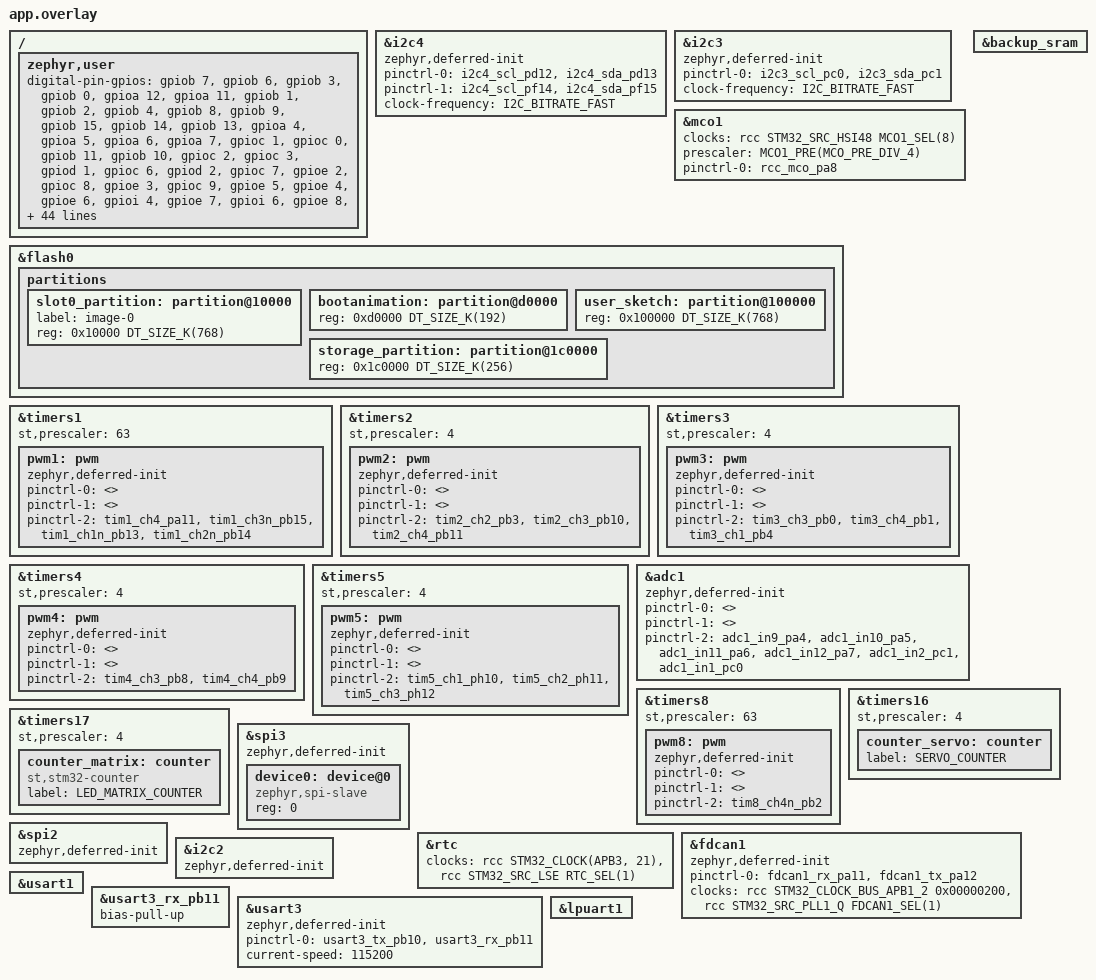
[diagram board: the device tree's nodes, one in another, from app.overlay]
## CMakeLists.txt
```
cmake_minimum_required(VERSION 3.20.0)

set(BOARD_VARIANT "arduino_uno_q")

find_package(Zephyr REQUIRED HINTS $ENV{ZEPHYR_BASE})


#set(ARDUINO_CORE_DIR "~/.arduino15/packages/arduino/hardware/zephyr/0.90.0")
#set(ZEPHYR_EXTRA_MODULES ${ARDUINO_CORE_DIR} )

set(ZEPHYR_EXTRA_MODULES 
    "${ZEPHYR_BASE}/../modules/lib/arduinocore-zephyr"
)

project(myTestSketch)

#set(ARDUINO_CORE_DIR "~/.arduino15/packages/arduino/hardware/zephyr/0.90.0")
set(ARDUINO_CORE_DIR ${ZEPHYR_EXTRA_MODULES})
set(LIB_DIR "~/Arduino/libraries")

target_sources(app PRIVATE 
    src/main.cpp
    ${LIB_DIR}/RF24Ethernet/drivers/net/rf24_netif.c
    ${ARDUINO_CORE_DIR}/cores/arduino/Arduino.h
    ${LIB_DIR}/Arduino_RouterBridge/src/singletons.cpp
    ${LIB_DIR}/Arduino_RouterBridge/src/Arduino_RouterBridge.h
    ${LIB_DIR}/Arduino_RouterBridge/src/routerbridge_provides_serial.h
    ${LIB_DIR}/Arduino_RouterBridge/src/bridge.h
    ${LIB_DIR}/Arduino_RouterBridge/src/monitor.h
    ${LIB_DIR}/ArduinoGraphics/src/ArduinoGraphics.cpp
    ${LIB_DIR}/ArduinoGraphics/src/Image.cpp
    ${LIB_DIR}/RF24/RF24.cpp
    ${LIB_DIR}/RF24Network/RF24Network.cpp
    ${LIB_DIR}/RF24Mesh/RF24Mesh.cpp
    ${LIB_DIR}/RF24Ethernet/RF24Ethernet.cpp
    ${LIB_DIR}/RF24Ethernet/RF24Client.cpp
    ${LIB_DIR}/RF24Ethernet/RF24Server.cpp
    ${LIB_DIR}/RF24Ethernet/RF24Udp.cpp
    ${LIB_DIR}/RF24Ethernet/Dns.cpp
    ${LIB_DIR}/Arduino_RPClite/src/Arduino_RPClite.h
    ${ARDUINO_CORE_DIR}/cores/arduino/new.cpp
)

target_include_directories(app PRIVATE
    #drivers/net
    "${ARDUINO_CORE_DIR}/cores/arduino"
    "${ARDUINO_CORE_DIR}/cores/arduino/api"
    "${ARDUINO_CORE_DIR}/variants/arduino_uno_q_stm32u585xx"
    "${ARDUINO_CORE_DIR}/libraries/SPI"
    "${LIB_DIR}/Arduino_RPClite/src"
    "${LIB_DIR}/MsgPack"
    "${LIB_DIR}/DebugLog"
    "${LIB_DIR}/ArxTypeTraits"
    "${LIB_DIR}/ArxContainer"
    "${LIB_DIR}/RF24"
    "${LIB_DIR}/RF24Network"
    "${LIB_DIR}/RF24Mesh"
    "${LIB_DIR}/RF24Ethernet"
    "${ARDUINO_CORE_DIR}/libraries/Arduino_LED_Matrix/src"
    "${LIB_DIR}/ArduinoGraphics/src"
    "${LIB_DIR}/Arduino_RouterBridge/src"
    ${ZEPHYR_BASE}/../modules/lib/arduinocore-zephyr/loader/
)

target_compile_definitions(app PRIVATE 
    -DCONFIG_BOARD_ARDUINO_UNO_Q
    -DARDUINO_VARIANT="arduino_uno_q_stm32u585xx"
    -DUSE_LWIP=2
    -DRF24ETHERNET_USE_UDP=1
    -DARDUINO
 )
```

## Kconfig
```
# 1. Pull in the baseline Zephyr main Kconfig definitions
source "Kconfig.zephyr"
```

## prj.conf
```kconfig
CONFIG_SERIAL=y
CONFIG_CONSOLE=y
CONFIG_UART_CONSOLE=y


CONFIG_THREAD_LOCAL_STORAGE=n
# Force the build system to initialize the TLS runtime tables
#CONFIG_COMPILER_OPT="-ftls-model=local-exec"
CONFIG_ARM_TRUSTZONE_M=n
CONFIG_TRUSTED_EXECUTION_NONSECURE=y
CONFIG_TRUSTED_EXECUTION_SECURE=y
CONFIG_BUILD_WITH_TFM=y

CONFIG_USB_DEVICE_STACK=n
CONFIG_USB_CDC_ACM=n
CONFIG_USB_DEVICE_INITIALIZE_AT_BOOT=n
CONFIG_USB_DEVICE_PRODUCT="Zephyr Monitor"

CONFIG_LOG=n
CONFIG_LOG_MODE_IMMEDIATE=y


CONFIG_GPIO=y
CONFIG_ARDUINO_ENTRY=y
CONFIG_CPP=y
CONFIG_STD_CPP17=y
CONFIG_GLIBCXX_LIBCPP=y
CONFIG_NEWLIB_LIBC=y
#CONFIG_MINIMAL_LIBC=n

#CONFIG_GLIBCXX_LIBCPP=y
#CONFIG_STD_CPP17=y
#CONFIG_REQUIRES_FULL_LIBCPP=y

CONFIG_SPI=y

# Enable standard device model structures
CONFIG_DEVICE_DEPS=y
CONFIG_POLL=y

CONFIG_SPI_ASYNC=y
CONFIG_SPI_STM32_DMA=n

# Expand stack frames to prevent RTOS buffer overflows
CONFIG_MAIN_STACK_SIZE=16384
CONFIG_SYSTEM_WORKQUEUE_STACK_SIZE=4096
CONFIG_ARDUINO_API=y

CONFIG_LLEXT=n
CONFIG_LLEXT_TYPE_ELF_OBJECT=y

CONFIG_FAULT_DUMP=2
#CONFIG_RESET_ON_FATAL_ERROR=n
CONFIG_FLASH=y
CONFIG_FLASH_MAP=n
CONFIG_MPU_ALLOW_FLASH_WRITE=y
CONFIG_COUNTER=y

CONFIG_USB_DEVICE_VID=0x239A
CONFIG_USB_DEVICE_PID=0x239A

CONFIG_PRINTK=y
CONFIG_SHELL=n
CONFIG_SHELL_BACKEND_SERIAL=y
CONFIG_STDOUT_CONSOLE=y
CONFIG_LOG_BACKEND_UART=y

CONFIG_HEAP_MEM_POOL_SIZE=16384
CONFIG_LLEXT_HEAP_SIZE=256

#CONFIG_FPU=y

CONFIG_ADC=n
CONFIG_DAC=y
CONFIG_PWM=n
CONFIG_I2C_TARGET=y
#CONFIG_DMA=y
CONFIG_MEMC=y
#CONFIG_SPI_ASYNC=y
#CONFIG_SPI_STM32_INTERRUPT=y
#CONFIG_SPI_SLAVE=y
#CONFIG_CAN=y
#CONFIG_CAN_FD_MODE=y
CONFIG_UART_INTERRUPT_DRIVEN=n
CONFIG_UART_LINE_CTRL=y
CONFIG_RTC_STM32=y

CONFIG_DEBUG=y

CONFIG_NET_SOCKETS_SOCKOPT_TLS=n

# Disable TLS credentials management
CONFIG_TLS_CREDENTIALS=n

# Disable Mbed TLS if it is no longer needed by other components
CONFIG_MBEDTLS=n
CONFIG_BOOTLOADER_MCUBOOT=n

CONFIG_DYNAMIC_THREAD=y
CONFIG_DYNAMIC_THREAD_PREFER_ALLOC=y

# Allocate a system heap. Stacks need alignment, so make this 
# significantly larger than your requested stack size.
CONFIG_DYNAMIC_OBJECTS=y
CONFIG_USERSPACE=n
CONFIG_THREAD_STACK_INFO=y
CONFIG_INIT_STACKS=y
CONFIG_DYNAMIC_THREAD_POOL_SIZE=3
CONFIG_DYNAMIC_THREAD_STACK_SIZE=4096

CONFIG_NETWORKING=y
CONFIG_NET_SOCKETS=y

CONFIG_NET_IPV4=y
CONFIG_NET_IPV6=n
CONFIG_NET_TCP=y
CONFIG_NET_UDP=y


CONFIG_NET_PKT_RX_COUNT=24
CONFIG_NET_PKT_TX_COUNT=24
CONFIG_NET_BUF_RX_COUNT=48
CONFIG_NET_BUF_TX_COUNT=48
CONFIG_NET_CONTEXT_NET_PKT_POOL=y

CONFIG_NET_L2_VIRTUAL=n
CONFIG_NET_L2_DUMMY=y

#CONFIG_NET_L2_ETHERNET=n
#CONFIG_NET_ARP=n

CONFIG_NET_TCP_LOG_LEVEL_DBG=n
CONFIG_NET_IPV4_LOG_LEVEL_DBG=n
CONFIG_NET_CORE_LOG_LEVEL_DBG=n
CONFIG_NET_LOG=n
#CONFIG_NET_CONTEXT_LOG_LEVEL_DBG=y
CONFIG_NET_PKT_LOG_LEVEL_DBG=n

CONFIG_NET_PPP=n
CONFIG_NET_TCP_CHECKSUM=n
CONFIG_NET_UDP_CHECKSUM=n

CONFIG_POSIX_API=y
CONFIG_NET_SOCKETS_OFFLOAD=n
CONFIG_NET_RX_STACK_SIZE=8192
CONFIG_NET_TX_STACK_SIZE=8192

CONFIG_NET_IF_UNICAST_IPV4_ADDR_COUNT=2
CONFIG_NET_MAX_CONTEXTS=2

CONFIG_LOG_MODE_DEFERRED=y
CONFIG_LOG_BUFFER_SIZE=16384
CONFIG_LOG_PROCESS_THREAD_STACK_SIZE=4096
CONFIG_COMMON_LIBC_MALLOC_ARENA_SIZE=16384
CONFIG_NET_MAX_CONN=2

CONFIG_NET_TCP_RETRY_COUNT=5


CONFIG_SYS_HEAP_VALIDATE=y

# Catch thread stack overflows immediately via hardware MPU
CONFIG_HW_STACK_PROTECTION=n

# Identify the exact thread causing issues
CONFIG_THREAD_NAME=y
CONFIG_NET_MGMT_EVENT_STACK_SIZE=2048
CONFIG_ZBUS_OBSERVER_NAME=n
```

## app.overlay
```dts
/*
 * Copyright (c) Arduino s.r.l. and/or its affiliated companies
 *
 * SPDX-License-Identifier: Apache-2.0
 */
#include <zephyr/dt-bindings/pwm/stm32_pwm.h>
&i2c4 {
	status = "okay";
	zephyr,deferred-init;
	pinctrl-0 = <&i2c4_scl_pd12 &i2c4_sda_pd13>;
	pinctrl-1 = <&i2c4_scl_pf14 &i2c4_sda_pf15>;
	pinctrl-names = "default", "sleep"; /* TODO: sleep is jmisc mux */
	clock-frequency = <I2C_BITRATE_FAST>;

/*
	gc2145: gc2145@3c {
		status = "okay";
		compatible = "galaxycore,gc2145";
		reg = <0x3c>;
		reset-gpios = <&gpioa 10 GPIO_ACTIVE_LOW>;
		pwdn-gpios = <&gpiod 2 GPIO_ACTIVE_LOW>;

		port {
			gc2145_ep_out: endpoint {
				remote-endpoint = <&dcmi_ep_in>;
			};
		};
	};
*/
};

&i2c3 {
	status = "okay";
	zephyr,deferred-init;
	pinctrl-0 = <&i2c3_scl_pc0 &i2c3_sda_pc1>;
	pinctrl-names = "default"; 
	clock-frequency = <I2C_BITRATE_FAST>;
};

/* clock from HSI48 */
&mco1 {
	status = "okay";
	clocks = <&rcc STM32_SRC_HSI48 MCO1_SEL(8)>;
	prescaler = <MCO1_PRE(MCO_PRE_DIV_4)>;
	pinctrl-0 = <&rcc_mco_pa8>;
	pinctrl-names = "default";
};

&backup_sram {
	status = "okay";
};

/*
&dcmi {
	status = "okay";
	pinctrl-0 = <&dcmi_hsync_pd8 &dcmi_pixclk_pd9 &dcmi_vsync_pi5
				&dcmi_d0_pc6 &dcmi_d1_pc7 &dcmi_d2_pc8 &dcmi_d3_pc9
				&dcmi_d4_pe4 &dcmi_d5_pi4 &dcmi_d6_pi6 &dcmi_d7_pi7>;
	pinctrl-names = "default";
	dmas = <&gpdma1 12 86 (STM32_DMA_PERIPH_TO_MEMORY | STM32_DMA_PERIPH_NO_INC |
			STM32_DMA_MEM_INC | STM32_DMA_PERIPH_32BITS | STM32_DMA_MEM_32BITS |
			STM32_DMA_PRIORITY_HIGH) STM32_DMA_FIFO_1_4>;

	port {
		dcmi_ep_in: endpoint {
			remote-endpoint-label = "gc2145_ep_out";
			bus-width = <8>;
			hsync-active = <0>;
			vsync-active = <0>;
			pclk-sample = <0>;
		};
	};
};
*/

/delete-node/ &slot0_partition;
/delete-node/ &slot1_partition;
/*/delete-node/ &scratch_partition;*/
/delete-node/ &storage_partition;

&flash0 {
	partitions {
		slot0_partition: partition@10000 {
			label = "image-0";
			reg = < 0x10000 DT_SIZE_K(768) >;
		};

		bootanimation: partition@d0000 {
			reg = < 0xd0000 DT_SIZE_K(192) >;
		};

		user_sketch: partition@100000 {
			reg = < 0x100000 DT_SIZE_K(768) >;
		};

		storage_partition: partition@1c0000 {
			reg = < 0x1c0000 DT_SIZE_K(256) >;
		};
	};
};

/* Enable PWM timers */
&timers1 {
	status = "okay";
	st,prescaler = <63>;

	pwm1: pwm {
		status = "okay";
		/* tim1_etr_pa12 is not available for PWM */
		zephyr,deferred-init;
		pinctrl-0 = <>;
		pinctrl-1 = <>;
		pinctrl-2 = <&tim1_ch4_pa11 &tim1_ch3n_pb15 &tim1_ch1n_pb13 &tim1_ch2n_pb14>;
		pinctrl-names = "default", "sleep", "arduino";
	};
};

/* Currently only the pins marked with ~ on the pin headers are enabled */
/* PB10 and PB11 conflict with I2C configuation */
&timers2 {
	status = "okay";
	st,prescaler = <4>;

	pwm2: pwm {
		status = "okay";
		zephyr,deferred-init;
		pinctrl-0 = <>;
		pinctrl-1 = <>;
		pinctrl-2 = <&tim2_ch2_pb3 &tim2_ch3_pb10 &tim2_ch4_pb11>;
		pinctrl-names = "default", "sleep", "arduino";
	};
};

&timers3 {
	status = "okay";
	st,prescaler = <4>;

	pwm3: pwm {
		status = "okay";
		zephyr,deferred-init;
		pinctrl-0 = <>;
		pinctrl-1 = <>;
		pinctrl-2 = <&tim3_ch3_pb0 &tim3_ch4_pb1 &tim3_ch1_pb4>;
		pinctrl-names = "default", "sleep", "arduino";
	};
};

&timers4 {
	status = "okay";
	st,prescaler = <4>;

	pwm4: pwm {
		status = "okay";
		zephyr,deferred-init;
		pinctrl-0 = <>;
		pinctrl-1 = <>;
		pinctrl-2 = <&tim4_ch3_pb8 &tim4_ch4_pb9 /*&tim4_ch1_pb6 &tim4_ch2_pb7*/>;
		pinctrl-names = "default", "sleep", "arduino";
	};
};

&timers5 {
    status = "okay";
	st,prescaler = <4>;

    pwm5: pwm {
        status = "okay";
        zephyr,deferred-init;
        pinctrl-0 = <>;
        pinctrl-1 = <>;
        pinctrl-2 = <&tim5_ch1_ph10 &tim5_ch2_ph11 &tim5_ch3_ph12>;
        pinctrl-names = "default", "sleep", "arduino";
    };
};

&adc1 {
	zephyr,deferred-init;
	pinctrl-0 = <>;
	pinctrl-1 = <>;
	pinctrl-2 = <&adc1_in9_pa4 &adc1_in10_pa5 &adc1_in11_pa6 &adc1_in12_pa7 &adc1_in2_pc1 &adc1_in1_pc0>;
	pinctrl-names = "default", "sleep", "arduino";
	status = "okay";
};

/* Currently only the pins marked with ~ on the pin headers are enabled */
&timers8 {
	status = "okay";
	st,prescaler = <63>;

	pwm8: pwm {
		status = "okay";
		zephyr,deferred-init;
		pinctrl-0 = <>;
		pinctrl-1 = <>;
		pinctrl-2 = <&tim8_ch4n_pb2>;
		pinctrl-names = "default", "sleep", "arduino";
	};
};

&timers16 {
	status = "okay";
	st,prescaler = <4>;

	counter_servo: counter {
		status = "okay";
		label = "SERVO_COUNTER";
	};
};


&timers17 {
	status = "okay";
	st,prescaler = <4>;

	counter_matrix: counter {
		status = "okay";
		label = "LED_MATRIX_COUNTER";
        compatible = "st,stm32-counter";
	};
};

&spi3 {
	zephyr,deferred-init;
	device0: device@0 {
        compatible = "zephyr,spi-slave";
        reg = <0>;
	};
};

&rtc {
    status = "okay";
    clocks = <&rcc STM32_CLOCK(APB3, 21)>,
             <&rcc STM32_SRC_LSE RTC_SEL(1)>;
};

&fdcan1 {
	status = "okay";
	zephyr,deferred-init;
	pinctrl-0 = <&fdcan1_rx_pa11 &fdcan1_tx_pa12>;
	pinctrl-names = "default";
	clocks = <&rcc STM32_CLOCK_BUS_APB1_2 0x00000200>,
		 <&rcc STM32_SRC_PLL1_Q FDCAN1_SEL(1)>;
};

&spi2 {
	zephyr,deferred-init;
};

&i2c2 {
	zephyr,deferred-init;
};

&usart1 {
	/* usart1 is not set as deferred-init to catch early boot logs since it is assigned to zephyr,console */
	status = "okay";
};

&usart3_rx_pb11 {
	bias-pull-up;
};

&usart3 {
	status = "okay";
	zephyr,deferred-init;
	pinctrl-0 = <&usart3_tx_pb10 &usart3_rx_pb11>;
	pinctrl-names = "default";
	current-speed = <115200>;
};


&lpuart1 {
	status = "okay";
};

/ {
	zephyr,user {
		digital-pin-gpios = <&gpiob 7 GPIO_ACTIVE_HIGH>, /* D0 - PB7 */
				    <&gpiob 6 GPIO_ACTIVE_HIGH>, /* D1 - PB6 */
				    <&gpiob 3 GPIO_ACTIVE_HIGH>, /* D2 - PB3 */
				    <&gpiob 0 GPIO_ACTIVE_HIGH>, /* D3 - PB0 */
				    <&gpioa 12 GPIO_ACTIVE_HIGH>, /* D4 - PA12 */
				    <&gpioa 11 GPIO_ACTIVE_HIGH>, /* D5 - PA11 */
				    <&gpiob 1 GPIO_ACTIVE_HIGH>, /* D6 - PB1 */
				    <&gpiob 2 GPIO_ACTIVE_HIGH>, /* D7 - PB2 */
				    <&gpiob 4 GPIO_ACTIVE_HIGH>, /* D8 - PB4 */
				    <&gpiob 8 GPIO_ACTIVE_HIGH>, /* D9 - PB8 */
				    <&gpiob 9 GPIO_ACTIVE_HIGH>, /* D10 - PB9 */
				    <&gpiob 15 GPIO_ACTIVE_HIGH>, /* D11 - PB15 */
				    <&gpiob 14 GPIO_ACTIVE_HIGH>, /* D12 - PB14 */
				    <&gpiob 13 GPIO_ACTIVE_HIGH>, /* D13 - PB13 */

					/* ADCs */
				    <&gpioa 4 GPIO_ACTIVE_HIGH>, /* A0 - PA4 */
				    <&gpioa 5 GPIO_ACTIVE_HIGH>, /* A1 - PA5 */
				    <&gpioa 6 GPIO_ACTIVE_HIGH>, /* A2 - PA6 */
				    <&gpioa 7 GPIO_ACTIVE_HIGH>, /* A3 - PA7 */
				    <&gpioc 1 GPIO_ACTIVE_HIGH>, /* A4 - PC1 */
				    <&gpioc 0 GPIO_ACTIVE_HIGH>, /* A5 - PC0 */

				    <&gpiob 11 GPIO_ACTIVE_HIGH>,  /* D20 - PB11 */
				    <&gpiob 10 GPIO_ACTIVE_HIGH>,  /* D21 - PB10 */

				    <&gpioc 2 GPIO_ACTIVE_HIGH>,        /* JSPI */
				    <&gpioc 3 GPIO_ACTIVE_HIGH>,
				    <&gpiod 1 GPIO_ACTIVE_HIGH>,

				    <&gpioc 6 GPIO_ACTIVE_HIGH>,	/* JMISC */
				    <&gpiod 2 GPIO_ACTIVE_HIGH>,
				    <&gpioc 7 GPIO_ACTIVE_HIGH>,
				    <&gpioe 2 GPIO_ACTIVE_HIGH>,
				    <&gpioc 8 GPIO_ACTIVE_HIGH>,
				    <&gpioe 3 GPIO_ACTIVE_HIGH>,
				    <&gpioc 9 GPIO_ACTIVE_HIGH>,
				    <&gpioe 5 GPIO_ACTIVE_HIGH>,
				    <&gpioe 4 GPIO_ACTIVE_HIGH>,
				    <&gpioe 6 GPIO_ACTIVE_HIGH>,
				    <&gpioi 4 GPIO_ACTIVE_HIGH>,
				    <&gpioe 7 GPIO_ACTIVE_HIGH>,
				    <&gpioi 6 GPIO_ACTIVE_HIGH>,
				    <&gpioe 8 GPIO_ACTIVE_HIGH>,
				    <&gpioi 7 GPIO_ACTIVE_HIGH>,
				    <&gpiof 14 GPIO_ACTIVE_HIGH>,
				    <&gpiod 9 GPIO_ACTIVE_HIGH>,
				    <&gpiof 15 GPIO_ACTIVE_HIGH>,
				    <&gpioi 5 GPIO_ACTIVE_HIGH>,
				    <&gpioa 3 GPIO_ACTIVE_HIGH>,
				    <&gpiod 8 GPIO_ACTIVE_HIGH>,
				    <&gpioa 0 GPIO_ACTIVE_HIGH>,
				    <&gpioa 8 GPIO_ACTIVE_HIGH>,
				    <&gpioa 1 GPIO_ACTIVE_HIGH>,
				    <&gpioa 10 GPIO_ACTIVE_HIGH>,

				    <&gpioh 10 GPIO_ACTIVE_HIGH>,        /* LEDs */
				    <&gpioh 11 GPIO_ACTIVE_HIGH>,
				    <&gpioh 12 GPIO_ACTIVE_HIGH>,
				    <&gpioh 13 GPIO_ACTIVE_HIGH>,
				    <&gpioh 14 GPIO_ACTIVE_HIGH>,
				    <&gpioh 15 GPIO_ACTIVE_HIGH>,

				    <&gpiof 0 GPIO_ACTIVE_HIGH>,        /* LED matrix */
				    <&gpiof 1 GPIO_ACTIVE_HIGH>,
				    <&gpiof 2 GPIO_ACTIVE_HIGH>,
				    <&gpiof 3 GPIO_ACTIVE_HIGH>,
				    <&gpiof 4 GPIO_ACTIVE_HIGH>,
				    <&gpiof 5 GPIO_ACTIVE_HIGH>,
				    <&gpiof 6 GPIO_ACTIVE_HIGH>,
				    <&gpiof 7 GPIO_ACTIVE_HIGH>,
				    <&gpiof 8 GPIO_ACTIVE_HIGH>,
				    <&gpiof 9 GPIO_ACTIVE_HIGH>,
				    <&gpiof 10 GPIO_ACTIVE_HIGH>,
				    <&gpiog 13 GPIO_ACTIVE_HIGH>,       /* Internal SPI RDY */
				    <&gpioa 2 GPIO_ACTIVE_HIGH>,        /* Analog switch for VREF */
				    <&gpioh 3 GPIO_ACTIVE_HIGH>;        /* BOOT0 */

		builtin-led-gpios = <&gpioh 10 GPIO_ACTIVE_HIGH>,
				    <&gpioh 11 GPIO_ACTIVE_HIGH>,
				    <&gpioh 12 GPIO_ACTIVE_HIGH>,
				    <&gpioh 13 GPIO_ACTIVE_HIGH>,
				    <&gpioh 14 GPIO_ACTIVE_HIGH>,
				    <&gpioh 15 GPIO_ACTIVE_HIGH>;

		/* PWM pin mapping - Digital pins with their timer channels */
		/* Currently only the pins marked with ~ on the pin headers are enabled */
		pwm-pin-gpios =	
				/*<&gpiob 7 0>,*/    /* D0/PB6 - TIM4_CH2 */
				/*<&gpiob 6 0>,*/    /* D1/PB6 - TIM4_CH1 */
				<&gpiob 3 0>,    /* D2/PB3 - TIM2_CH2 */
				<&gpiob 0 0>,    /* D3/PB0 - TIM3_CH3 */
				<&gpioa 11 0>,   /* D5/PA11 - TIM1_CH4 */
				<&gpiob 1 0>,    /* D6/PB1 - TIM3_CH4 */
				<&gpiob 2 0>,    /* D7/PB2 - TIM8_CH4N */
				<&gpiob 4 0>,    /* D8/PB4 - TIM3_CH1 */
				<&gpiob 8 0>,    /* D9/PB8 - TIM4_CH3 */
				<&gpiob 9 0>,    /* D10/PB9 - TIM4_CH4 */
				<&gpiob 15 0>,   /* D11/PB15 - TIM1_CH3N */
				<&gpiob 14 0>,   /* D12/PB14 - TIM1_CH2N */
				<&gpiob 13 0>,   /* D13/PB13 - TIM1_CH1N */
				<&gpiob 11 0>,   /* D20/PB11 - TIM2_CH4 */
				<&gpiob 10 0>,   /* D21/PB10 - TIM2_CH3 */
				<&gpioh 10 0>,   /* LED3_R - TIM5_CH1 */
				<&gpioh 11 0>,   /* LED3_G - TIM5_CH2 */
				<&gpioh 12 0>;   /* LED3_B - TIM5_CH3 */

		adc-pin-gpios =	<&gpioa 4 0>,
					<&gpioa 5 0>,
					<&gpioa 6 0>,
					<&gpioa 7 0>,
					<&gpioc 1 0>,
					<&gpioc 0 0>;

		arduino,router-serial = <&lpuart1>; /* 'Serial' is provided by the Monitor */
		serials = <&usart1>, <&lpuart1>, <&usart3>;
		cans = <&fdcan1>;
		i2cs = <&i2c2>, <&i2c4>, <&i2c3>;
		spis = <&spi2>, <&spi3>;
		/* PWM mapping for the digital pins  */
		/* Currently only the pins marked with ~ on the pin headers are enabled */
		pwms = 
		       /*<&pwm4 2 PWM_HZ(500) PWM_POLARITY_NORMAL>,*/   /* D0/PB7 → TIM4_CH2 */
		       /*<&pwm4 1 PWM_HZ(500) PWM_POLARITY_NORMAL>,*/   /* D1/PB6 → TIM4_CH1 */
		       <&pwm2 2 PWM_HZ(500) PWM_POLARITY_NORMAL>,   /* D2/PB3 → TIM2_CH2 */
		       <&pwm3 3 PWM_HZ(500) PWM_POLARITY_NORMAL>,   /* D3/PB0 → TIM3_CH3 */
		       <&pwm1 4 PWM_HZ(500) PWM_POLARITY_NORMAL>,   /* D5/PA11 → TIM1_CH4 */
		       <&pwm3 4 PWM_HZ(500) PWM_POLARITY_NORMAL>,   /* D6/PB1 → TIM3_CH4 */
		       <&pwm8 4 PWM_HZ(500) (PWM_POLARITY_NORMAL | STM32_PWM_COMPLEMENTARY)>, /* D7/PB2 → TIM8_CH4N */
		       <&pwm3 1 PWM_HZ(500) PWM_POLARITY_NORMAL>,   /* D8/PB4 → TIM3_CH1 */
		       <&pwm4 3 PWM_HZ(500) PWM_POLARITY_NORMAL>,   /* D9/PB8 → TIM4_CH3 */
		       <&pwm4 4 PWM_HZ(500) PWM_POLARITY_NORMAL>,   /* D10/PB9 → TIM4_CH4 */
		       <&pwm1 3 PWM_HZ(500) (PWM_POLARITY_NORMAL | STM32_PWM_COMPLEMENTARY)>, /* D11/PB15 → TIM1_CH3N */
		       <&pwm1 2 PWM_HZ(500) (PWM_POLARITY_NORMAL | STM32_PWM_COMPLEMENTARY)>, /* D12/PB14 → TIM1_CH2N */
		       <&pwm1 1 PWM_HZ(500) (PWM_POLARITY_NORMAL | STM32_PWM_COMPLEMENTARY)>, /* D13/PB13 → TIM1_CH1N */
		       <&pwm2 4 PWM_HZ(500) PWM_POLARITY_NORMAL>,   /* D20/PB11 → TIM2_CH4 */
		       <&pwm2 3 PWM_HZ(500) PWM_POLARITY_NORMAL>,   /* D21/PB10 → TIM2_CH3 */
		       <&pwm5 1 PWM_HZ(500) PWM_POLARITY_INVERTED>,   /* LED3_R/PH10 → TIM5_CH1 */
		       <&pwm5 2 PWM_HZ(500) PWM_POLARITY_INVERTED>,   /* LED3_G/PH11 → TIM5_CH2 */
		       <&pwm5 3 PWM_HZ(500) PWM_POLARITY_INVERTED>;   /* LED3_B/PH12 → TIM5_CH3 */

		control-gpios = <&gpiog 13 GPIO_ACTIVE_HIGH>;    /* Internal SPI RDY */
		analog-switch-gpios = <&gpioa 2 GPIO_ACTIVE_HIGH>;    /* Analog switch for VREF */

		io-channels =	<&adc1 9>,     /* A0 - PA4 */
				<&adc1 10>,   /* A1 - PA5 */
				<&adc1 11>,   /* A2 - PA6 */
				<&adc1 12>,   /* A3 - PA7 */
				<&adc1 2>,    /* A4 - PC1 */
				<&adc1 1>;    /* A5 - PC0 */

		dac-pin-gpios =	<&gpioa 4 0>,
				<&gpioa 5 0>;

		dac = <&dac1>;
		dac-channels = <1>, <2>;
		dac-resolution = <12>;
	};
};
```

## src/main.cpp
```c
/*
 * RF24Ethernet InteractiveServer example by TMRh20
 * - Webserver controlling an LED example
 *
 * RF24Ethernet uses the uIP stack by Adam Dunkels <adam@sics.se>
 *
 * This example demonstrates how to configure a Headless Master node running an HTTP server
 * It does NOT require a Gateway node, just two nodes running RF24Ethernet
 *
 */

#define OUTPUT_BUFFER_SIZE MAX_PAYLOAD_SIZE - 14



//*********************** USER CONFIG ***********************
// Comment this out to use the nrf_to_nrf driver for nRF52 radios
#define USE_NRF24
//**********************************************************

#ifdef USE_NRF24
#include <RF24.h>
#include <RF24Network.h>
#include "RF24Mesh.h"
#include <RF24Ethernet.h>
#include "HTML.h"

RF24 radio(7, 8);
RF24Network network(radio);
RF24Mesh mesh(radio, network);
RF24EthernetClass RF24Ethernet(radio, network, mesh);
#else
#include <nrf_to_nrf.h>
#include <RF24Network.h>
#include "RF24Mesh.h"
#include <RF24Ethernet.h>
#include "HTML.h"
nrf_to_nrf radio;
RF52Network network(radio);
RF52Mesh mesh(radio, network);
RF52EthernetClass RF24Ethernet(radio, network, mesh);
#endif

#if defined(ARDUINO_ARCH_ESP8266)
#define LED_PIN BUILTIN_LED
#else
#define LED_PIN 5  //Analog pin A3
#endif

#include <Arduino_RouterBridge.h>

// Configure the server to listen on port 1000
EthernetServer server = EthernetServer(80);

/**********************************************************/
static unsigned short generate_tcp_stats();

void setup() {

  Bridge.begin();
  Serial.begin(115200);
  //while (!Serial) {}
  //printf_begin();
  Serial.println("start");
  pinMode(LED_PIN, OUTPUT);

  IPAddress myIP(10, 1, 3, 1);
  Ethernet.begin(myIP);

  //Set IP of the RPi (gateway)
  IPAddress gwIP(10, 1, 3, 2);
  Ethernet.set_gateway(gwIP);

  // Make this a Master node
  mesh.setNodeID(0);
  Serial.println(mesh.getNodeID());
  radio.begin();
  radio.setPALevel(RF24_PA_LOW,0);
  mesh.begin(25);

  server.begin();
  server.setTimeout(30000);
  


}

/********************************************************/

uint32_t mesh_timer = 0;
uint32_t printTimer = 0;


void loop() {


  Ethernet.update();
  mesh.DHCP();

  EthernetClient client = server.available();
  if (client) {
    uint8_t pageReq = 0;
    char requestBuffer[20];
    memset(requestBuffer, 0, sizeof(requestBuffer));

    uint32_t timeout = millis();

    while (client.connected() && (millis() - timeout < 100)) {
      if (client.available()) {

        char c = client.read();
        if (c == '/') {
          int bytesRead = 0;
          if (client.available() >= 2) {
            client.readBytes(requestBuffer, 2);
          }
          break;
        }
      }
    }

    if (strncmp(requestBuffer, "ON", 2) == 0) {
      led_state = 1;
      pageReq = 1;
      digitalWrite(LED_PIN, led_state);
    } else if (strncmp(requestBuffer, "OF", 2) == 0) {
      led_state = 0;
      pageReq = 1;
      digitalWrite(LED_PIN, led_state);
    } else if (strncmp(requestBuffer, "ST", 2) == 0) {
      pageReq = 2;
    } else if (strncmp(requestBuffer, "CR", 2) == 0) {
      pageReq = 3;
    } else {
      pageReq = 4;  // Default to main
    }

    //client.flush();

    switch (pageReq) {
      case 2: stats_page(client); break;
      case 3: credits_page(client); break;
      default: main_page(client); break;
    }
    uint32_t drainStart = millis();
    while (client.connected() && (millis() - drainStart < 20)) {
      while (client.available()) client.read();
    }
    client.stop();
    Serial.println(F("********"));
  }

  // We can do other things in the loop, but be aware that the loop will
  // briefly pause while IP data is being processed.
}

/**
* This section displays some basic connection stats via Serial and demonstrates
* how to interact directly with the uIP TCP/IP stack
* See the uIP documentation for more info
*/
static unsigned short generate_tcp_stats() {
  /*struct uip_conn* conn;

  // If multiple connections are enabled, get info for each active connection
  for (uint8_t i = 0; i < UIP_CONF_MAX_CONNECTIONS; i++) {
    conn = &uip_conns[i];

    // If the application state is active for an available connection, print the info
    if (conn->appstate) {
      Serial.print(F("Connection no "));
      Serial.println(i);
      Serial.print(F("Local Port "));
      Serial.println(htons(conn->lport));
      Serial.print(F("Remote IP/Port "));
      Serial.print(htons(conn->ripaddr[0]) >> 8);
      Serial.print(F("."));
      Serial.print(htons(conn->ripaddr[0]) & 0xff);
      Serial.print(F("."));
      Serial.print(htons(conn->ripaddr[1]) >> 8);
      Serial.print(F("."));
      Serial.print(htons(conn->ripaddr[1]) & 0xff);
      Serial.print(F(":"));
      Serial.println(htons(conn->rport));
      Serial.print(F("Outstanding "));
      Serial.println((uip_outstanding(conn)) ? '*' : ' ');
    }
  }*/
  return 1;
}
```

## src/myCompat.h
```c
#include <new>
#include <cstddef>
#include <cstdint>

void* operator new(std::size_t, void* p) noexcept { return p; }
void* operator new[](std::size_t, void* p) noexcept { return p; }

void operator delete(void*, void*) noexcept {}
void operator delete[](void*, void*) noexcept {}

#include <Arduino.h>
#include <Arduino_RouterBridge.h>
BridgeClass Bridge(Serial);
BridgeMonitor<> Monitor(Bridge);
```
